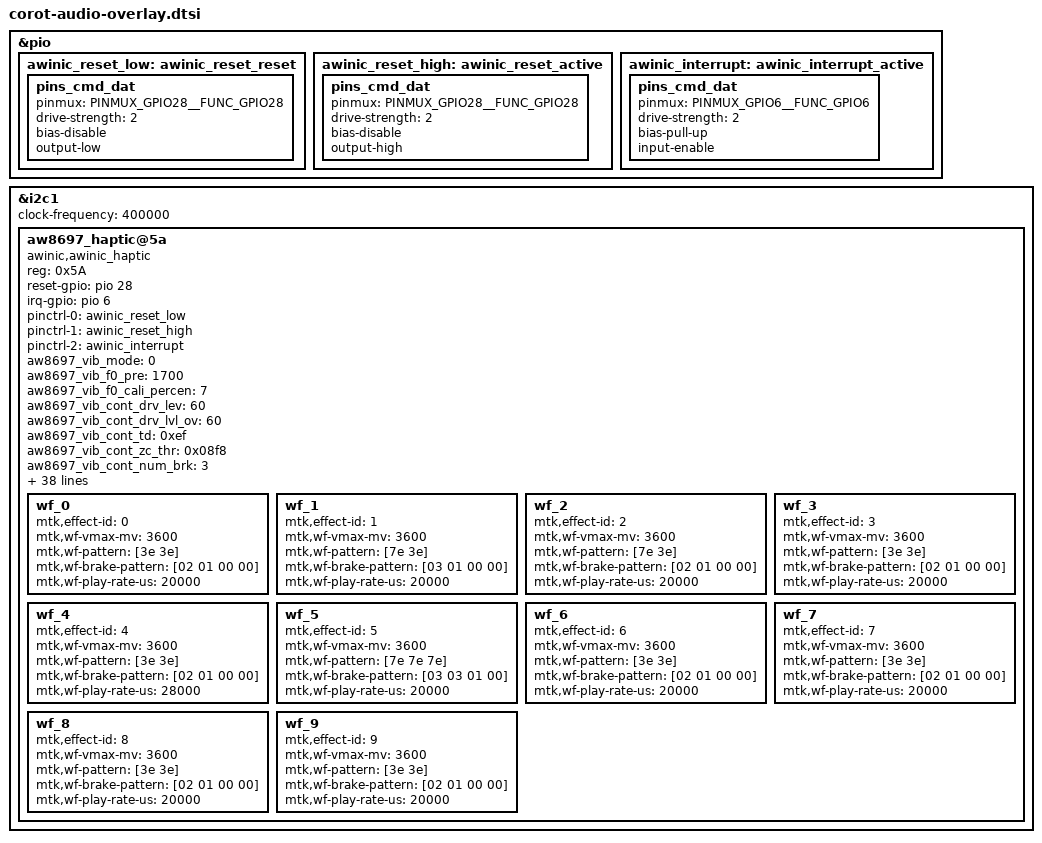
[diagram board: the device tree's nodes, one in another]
/* AW8697 Haptic start */
&pio {
	awinic_reset_low: awinic_reset_reset {
		pins_cmd_dat {
			pinmux = <PINMUX_GPIO28__FUNC_GPIO28>;
			drive-strength = <2>;
			bias-disable;
			output-low;
		};
	};
	awinic_reset_high: awinic_reset_active {
		pins_cmd_dat {
			pinmux = <PINMUX_GPIO28__FUNC_GPIO28>;
			drive-strength = <2>;
			bias-disable;
			output-high;
		};
	};
	awinic_interrupt: awinic_interrupt_active {
		pins_cmd_dat {
			pinmux = <PINMUX_GPIO6__FUNC_GPIO6>;
			drive-strength = <2>;
			bias-pull-up;
			input-enable;
		};
	};
};

&i2c1 {
    clock-frequency = <400000>;
	status = "ok";
        aw8697_haptic@5a {
		compatible = "awinic,awinic_haptic";
		reg = <0x5A>;
		reset-gpio = <&pio 28 0>;
		irq-gpio = <&pio 6 0>;
		pinctrl-names = "awinic_reset_reset","awinic_reset_active","awinic_interrupt_active";
		pinctrl-0 = <&awinic_reset_low>;
		pinctrl-1 = <&awinic_reset_high>;
		pinctrl-2 = <&awinic_interrupt>;
		/*----------------------aw8697----------------------*/
		aw8697_vib_mode = < 0 >; /*mode:   RAM mode->0; CONT mode -> 1*/
		aw8697_vib_f0_pre = < 1700 >;
		aw8697_vib_f0_cali_percen = < 7 >;
		aw8697_vib_cont_drv_lev = < 60 >;
		aw8697_vib_cont_drv_lvl_ov = < 60 >;
		aw8697_vib_cont_td = < 0xef >;
		aw8697_vib_cont_zc_thr = < 0x08f8 >;  /*hq 0x08F8 */
		aw8697_vib_cont_num_brk = < 3 >;
		aw8697_vib_f0_coeff = < 260 >; /*Don't modify it 2.604167*/
		aw8697_vib_f0_trace_parameter = < 9 3 1 31 >;
		aw8697_vib_bemf_config = < 0 0x08 0x03 0xf8 >;
		aw8697_vib_sw_brake = < 0x2c >;
		aw8697_vib_tset = < 0x1a >;
		aw8697_vib_r_spare = < 0x68 >;
		aw8697_vib_bstdbg = < 0x30 0xeb 0xd4 0 0 0 >;
		aw8697_vib_trig_config = < 0 1 0 1 2
					   0 1 0 1 2
					   0 1 0 1 2 >;
		aw8697_vib_bst_vol_default = < 0x0e >;
		aw8697_vib_bst_vol_ram = < 0x0e >;
		aw8697_vib_bst_vol_rtp = < 0x0e >;
		/*----------------------aw8692x----------------------*/
		aw86927_vib_mode = < 0 >; /* mode: RAM mode->0; CONT mode->1 */
		aw86927_vib_f0_pre = < 1700 >;
		aw86927_vib_f0_cali_percen = < 7 >;
		aw86927_vib_cont_drv1_lvl = < 0x7F >;
		aw86927_vib_cont_drv2_lvl = < 0x36 >;
		aw86927_vib_cont_drv1_time = < 0x04 >;
		aw86927_vib_cont_drv2_time = < 0x06 >;
		aw86927_vib_cont_drv_width = < 0x6A >;
		aw86927_vib_cont_wait_num = < 0x06 >;
		aw86927_vib_cont_brk_time = < 0x08 >;
		aw86927_vib_cont_track_margin = < 0x0C >;
		aw86927_vib_brk_bst_md = < 0 >;
		aw86927_vib_cont_tset = < 0x06 >;
		aw86927_vib_cont_bemf_set = < 0x02 >;
		aw86927_vib_cont_bst_brk_gain = < 0x05 >;
		aw86927_vib_cont_brk_gain = < 0x08 >;
		aw86927_vib_d2s_gain = < 0x04 >;
		aw86927_vib_trig_config = < 1 0 1 1 1 2 0 0
					    1 0 0 1 0 2 0 0
					    1 0 0 1 0 2 0 0 >;
		aw86927_vib_bst_vol_default = < 0x58 >;
		aw86927_vib_bst_vol_ram = < 0x4C >;
		aw86927_vib_bst_vol_rtp = < 0x4C >;
		/*--------------------common--------------------*/
		vib_effect_id_boundary = < 10 >;
		vib_effect_max = < 197 >; /*vib_effect_max must bigger than vib_effect_id*/
		vib_rtp_time = < 20 20 20 20 20 20 20 20 20000 15000
				15000 20000 25000 15000 30000 25000 20000 20000 20000 20000
				20000 20000 20000 20000 20000 20000 20000 20000 20000 20000
				20000 20000 20000 20000 20000 20000 20000 20000 20000 20000
				20000 20000 20000 20000 20000 20000 20000 20000 20000 20000
				20000 20000 20000 20000 20000 20000 20000 20000 20000 20000
				20000 20000 20000 20000 20000 20000 20000 20000 20000 20000
				20000 20000 20000 20000 20000 20000 20000 20000 20000 20000
				20000 20000 20000 20000 20000 20000 20000 20000 20000 20000
				20000 20000 20000 20000 20000 20000 20000 20000 20000 20000
				20000 20000 20000 20000 20000 20000 20000 20000 20000 20000
				20000 20000 20000 20000 20000 20000 20000 20000 20000 20000
				20000 20000 20000 20000 20000 20000 20000 20000 20000 20000
				20000 20000 20000 20000 20000 20000 20000 20000 20000 20000
				20000 20000 20000 20000 20000 20000 20000 20000 20000 20000
				20000 20000 20000 20000 20000 20000 20000 20000 20000 20000
				20000 20000 20000 20000 20000 20000 20000 20000 20000 20000
				20000 20000 20000 20000 20000 >;
		status = "ok";
		wf_0 {
			/*CLICK*/
			mtk,effect-id = <0>;
			mtk,wf-vmax-mv = <3600>;
			mtk,wf-pattern = [3e 3e];
			mtk,wf-brake-pattern = [02 01 00 00];
			mtk,wf-play-rate-us = <20000>;
		};
		wf_1 {
			/*DOUBLE CLICK*/
			mtk,effect-id = <1>;
			mtk,wf-vmax-mv = <3600>;
			mtk,wf-pattern = [7e 3e];
			mtk,wf-brake-pattern = [03 01 00 00];
			mtk,wf-play-rate-us = <20000>;
		};
		wf_2 {
			/*TICK*/
			mtk,effect-id = <2>;
			mtk,wf-vmax-mv = <3600>;
			mtk,wf-pattern = [7e 3e];
			mtk,wf-brake-pattern = [02 01 00 00];
			mtk,wf-play-rate-us = <20000>;
		};
		wf_3 {
			/*THUD*/
			mtk,effect-id = <3>;
			mtk,wf-vmax-mv = <3600>;
			mtk,wf-pattern = [3e 3e];
			mtk,wf-brake-pattern = [02 01 00 00];
			mtk,wf-play-rate-us = <20000>;
		};
		wf_4 {
			/*POP*/
			mtk,effect-id = <4>;
			mtk,wf-vmax-mv = <3600>;
			mtk,wf-pattern = [3e 3e];
			mtk,wf-brake-pattern = [02 01 00 00];
			mtk,wf-play-rate-us = <28000>;
		};
		wf_5 {
			/*HEAVY CLICK*/
			mtk,effect-id = <5>;
			mtk,wf-vmax-mv = <3600>;
			mtk,wf-pattern = [7e 7e 7e];
			mtk,wf-brake-pattern = [03 03 01 00];
			mtk,wf-play-rate-us = <20000>;
		};
		wf_6 {
			/*id 6*/
			mtk,effect-id = <6>;
			mtk,wf-vmax-mv = <3600>;
			mtk,wf-pattern = [3e 3e];
			mtk,wf-brake-pattern = [02 01 00 00];
			mtk,wf-play-rate-us = <20000>;
		};
		wf_7 {
			/*id 7*/
			mtk,effect-id = <7>;
			mtk,wf-vmax-mv = <3600>;
			mtk,wf-pattern = [3e 3e];
			mtk,wf-brake-pattern = [02 01 00 00];
			mtk,wf-play-rate-us = <20000>;
		};
		wf_8 {
			/*id 8*/
			mtk,effect-id = <8>;
			mtk,wf-vmax-mv = <3600>;
			mtk,wf-pattern = [3e 3e];
			mtk,wf-brake-pattern = [02 01 00 00];
			mtk,wf-play-rate-us = <20000>;
		};
		wf_9 {
			/*id 9*/
			mtk,effect-id = <9>;
			mtk,wf-vmax-mv = <3600>;
			mtk,wf-pattern = [3e 3e];
			mtk,wf-brake-pattern = [02 01 00 00];
			mtk,wf-play-rate-us = <20000>;
		};
	};
};
/* AW8697 Haptic end */
